# AT90PWM316 register map
Vendor: Atmel; File version: 1.0
CPU: other r0p0, little endian, no MPU, no FPU, 4 interrupt priority bits
Registers are 8-bit, read-write, reset 0x0 unless marked. A register's access mark holds for its fields unless they carry their own. Offsets are from the block's base; lines under a group give offsets from that group; [hi:lo] are bit positions; {n}, {i} and the like mark numbered series; 'fields as' and 'values as' point back to an identical list; <NAME> marks a mode.

## Memory map
0x00000000 FUSE size 0x3 — Fuses
0x00000000 LOCKBIT size 0x1 — Lockbits
0x00000023 PORTB size 0x3 — I/O Port
0x00000026 PORTC size 0x3 — I/O Port
0x00000029 PORTD size 0x3 — I/O Port
0x0000002C PORTE size 0x3 — I/O Port
0x00000035 TC0 blocks up to offset 0x3A — Timer/Counter, 8-bit
0x00000036 TC1 blocks up to offset 0x56 — Timer/Counter, 16-bit
0x00000039 CPU blocks up to offset 0x2E — CPU Registers
0x0000003C EXINT blocks up to offset 0x2E — External Interrupts
0x0000003F EEPROM size 0x4
0x0000004C SPI size 0x3 — Serial Peripheral Interface
0x00000050 AC blocks up to offset 0x60 — Analog Comparator
0x00000057 BOOT_LOAD size 0x1 — Bootloader
0x00000060 WDT size 0x1 — Watchdog Timer
0x00000076 ADC blocks up to offset 0xA — Analog-to-Digital Converter
0x000000A0 PSC0 blocks up to offset 0x40 — Power Stage Controller
0x000000A2 PSC1 blocks up to offset 0x4E — Power Stage Controller
0x000000A4 PSC2 blocks up to offset 0x5C — Power Stage Controller
0x000000AA DAC size 0x3 — Digital-to-Analog Converter
0x000000C0 USART blocks up to offset 0x7
0x000000C8 EUSART blocks up to offset 0x7 — Extended USART

## Interrupts
0 RESET (CPU) — External Pin, Power-on Reset, Brown-out Reset, Watchdog Reset and JTAG AVR Reset
1 PSC2_CAPT (CPU) — PSC2 Capture Event
2 PSC2_EC (CPU) — PSC2 End Cycle
3 PSC1_CAPT (CPU) — PSC1 Capture Event
4 PSC1_EC (CPU) — PSC1 End Cycle
5 PSC0_CAPT (CPU) — PSC0 Capture Event
6 PSC0_EC (CPU) — PSC0 End Cycle
7 ANALOG_COMP_0 (CPU) — Analog Comparator 0
8 ANALOG_COMP_1 (CPU) — Analog Comparator 1
9 ANALOG_COMP_2 (CPU) — Analog Comparator 2
10 INT0 (CPU) — External Interrupt Request 0
11 TIMER1_CAPT (CPU) — Timer/Counter1 Capture Event
12 TIMER1_COMPA (CPU) — Timer/Counter1 Compare Match A
13 TIMER1_COMPB (CPU) — Timer/Counter Compare Match B
14 RESERVED15 (CPU)
15 TIMER1_OVF (CPU) — Timer/Counter1 Overflow
16 TIMER0_COMP_A (CPU) — Timer/Counter0 Compare Match A
17 TIMER0_OVF (CPU) — Timer/Counter0 Overflow
18 ADC (CPU) — ADC Conversion Complete
19 INT1 (CPU) — External Interrupt Request 1
20 SPI_STC (CPU) — SPI Serial Transfer Complete
21 USART_RX (CPU) — USART, Rx Complete
22 USART_UDRE (CPU) — USART Data Register Empty
23 USART_TX (CPU) — USART, Tx Complete
24 INT2 (CPU) — External Interrupt Request 2
25 WDT (CPU) — Watchdog Timeout Interrupt
26 EE_READY (CPU) — EEPROM Ready
27 TIMER0_COMPB (CPU) — Timer Counter 0 Compare Match B
28 INT3 (CPU) — External Interrupt Request 3
29 RESERVED30 (CPU)
30 RESERVED31 (CPU)
31 SPM_READY (CPU) — Store Program Memory Read

## AC — Analog Comparator
Base 0x00000050
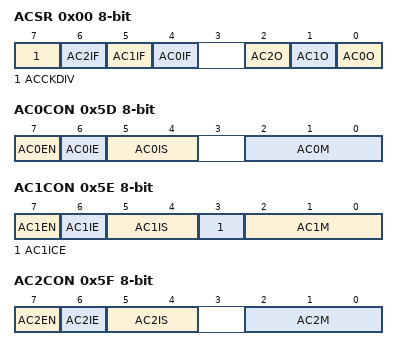
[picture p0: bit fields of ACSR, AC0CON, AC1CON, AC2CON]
0x00 ACSR — Analog Comparator Status Register
  [7] ACCKDIV — Analog Comparator Clock Divider
  [6] AC2IF — Analog Comparator 2 Interrupt Flag Bit
  [5] AC1IF — Analog Comparator 1 Interrupt Flag Bit
  [4] AC0IF — Analog Comparator 0 Interrupt Flag Bit
  [2] AC2O — Analog Comparator 2 Output Bit
  [1] AC1O — Analog Comparator 1 Output Bit
  [0] AC0O — Analog Comparator 0 Output Bit
0x5D AC0CON — Analog Comparator 0 Control Register
  [7] AC0EN — Analog Comparator 0 Enable Bit
  [6] AC0IE — Analog Comparator 0 Interrupt Enable Bit
  [5:4] AC0IS — Analog Comparator 0 Interrupt Select Bit
  [2:0] AC0M — Analog Comparator 0 Multiplexer Register
0x5E AC1CON — Analog Comparator 1 Control Register
  [7] AC1EN — Analog Comparator 1 Enable Bit
  [6] AC1IE — Analog Comparator 1 Interrupt Enable Bit
  [5:4] AC1IS — Analog Comparator 1 Interrupt Select Bit
    0=Interrupt on Toggle; 2=Interrupt on Falling Edge; 3=Interrupt on Rising Edge
  [3] AC1ICE — Analog Comparator 1 Interrupt Capture Enable Bit
  [2:0] AC1M — Analog Comparator 1 Multiplexer Register
0x5F AC2CON — Analog Comparator 2 Control Register
  [7] AC2EN — Analog Comparator 2 Enable Bit
  [6] AC2IE — Analog Comparator 2 Interrupt Enable Bit
  [5:4] AC2IS — Analog Comparator 2 Interrupt Select Bit
    values as AC1CON.AC1IS
  [2:0] AC2M — Analog Comparator 2 Multiplexer Register
